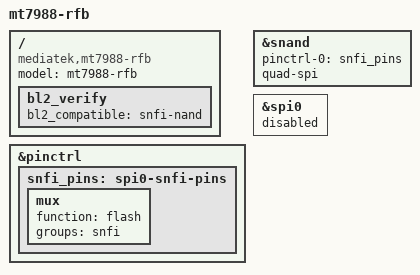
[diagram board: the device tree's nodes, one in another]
// SPDX-License-Identifier: GPL-2.0
/*
 * Copyright (c) 2022 MediaTek Inc.
 * Author: Sam Shih <sam.shih@mediatek.com>
 */

/dts-v1/;
#include "mt7988-rfb.dts"
#include <dt-bindings/gpio/gpio.h>

/ {
	model = "mt7988-rfb";
	compatible = "mediatek,mt7988-rfb", "mediatek,mt7988-snfi-nand-rfb";

	bl2_verify {
		bl2_compatible = "snfi-nand";
	};
};

&pinctrl {
	snfi_pins: spi0-snfi-pins {
		mux {
			function = "flash";
			groups = "snfi";
		};
	};
};

&snand {
	pinctrl-names = "default";
	pinctrl-0 = <&snfi_pins>;
	status = "okay";
	quad-spi;
};

&spi0 {
	status = "disabled";
};
